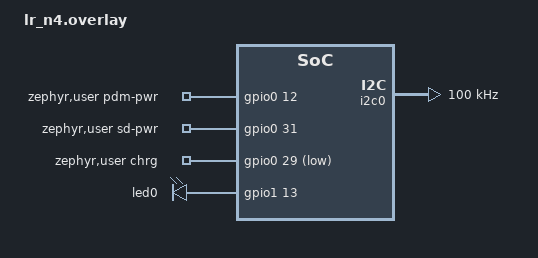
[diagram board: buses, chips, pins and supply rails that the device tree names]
/* LR-N4: our own board around a bare nRF52840 (QIAA, aQFN73), applied after lr_promicro.overlay. The same bootloader
 * and partitions as the ProMicro (nice!nano UF2 bootloader 0.10.0 on S140 6.1.1, the app at 0x26000), and the same
 * pins for the PDM mic (DAT P0.06, CLK P0.08), the SD card (CS P0.20, MOSI P0.22, SCK P0.24, MISO P1.00) and the slide
 * switch (P1.15 to GND = on, CONFIG_LR_SWITCH). What differs is below; the battery is read on AIN0 (P0.02) through a
 * 1M/1M divider (CONFIG_LR_BATTERY_AIN0, battery.c), and the charger's CHRG on P0.29 (chrg-gpios).
 *
 * Power: VDDH comes from the system rail (the battery, or USB through a Schottky diode while plugged in), so the chip
 * runs in high-voltage mode: REG0 (VDDH -> VDD) and REG1 (VDD -> DEC4), each with its DCDC inductor fitted (L1 on
 * DCCH; L3 + L4 on DCC, nRF52840 PS v1.11 7.3.4 configuration 4). The board's Kconfig has BOARD_ENABLE_DCDC and
 * BOARD_ENABLE_DCDC_HV on, and main.c sets DCDCEN and DCDCEN0. VDD is REG0's output, 3.0 V by UICR REGOUT0 = 4 (PS v1.11
 * 5.3.8 and the REGOUT0 register): it is written once with the bootloader over SWD, not by this firmware (the nice!nano
 * 0.10.0 bootloader writes 3.3 V there itself when it finds REGOUT0 erased, boards.c, so the UICR file goes in the same
 * load as the bootloader), and matches
 * the SD card's and the mics' 3.0 V LDOs (SGM2036-3.0), so their I/O levels agree. REG0 needs VDDH 0.3 V above it,
 * which is why the low-battery cut-off stays at 3.3 V (CONFIG_LR_LOW_BATTERY_MV). */
/ {
	zephyr,user {
		/* MIC_PWR: the enable of both mics' LDO (U5, 100k pull-down), not a supply from the pin as on LR-P3 */
		pdm-pwr-gpios = <&gpio0 12 0>;
		/* SD_EN: the card's LDO enable (U3, 100k pull-down) */
		sd-pwr-gpios = <&gpio0 31 GPIO_ACTIVE_HIGH>;
		/* CHRG: the charger's status (TP4054, open drain), read with the pull-up on for 50 us only (battery.c).
		 * LR-N5 / LR-N5-S swap the two balls: lr_n5.overlay, applied after this one, sets both */
		chrg-gpios = <&gpio0 29 GPIO_ACTIVE_LOW>;
	};
};

/* Two mics, MK1 and MK2, on the one CLK / DAT pair: MK1's L/R is tied to its supply and drives DAT on the clock's
 * rising edge, read on the falling edge, MK2's to GND drives the other half (DRA371 datasheet p.7). mic.c records mono
 * on the falling edge (NRF_PDM_MODE_MONO, NRF_PDM_EDGE_LEFTFALLING), LR-P3's setting: MK1 alone. MK2 alone: mono with
 * NRF_PDM_EDGE_LEFTRISING. Both: NRF_PDM_MODE_STEREO with LEFTFALLING, which interleaves MK1 (left) and MK2 (right)
 * samples in each buffer, so MIC_BUFFER_SAMPLES doubles and the codec takes one channel or a mix. */

/* D1's two dies, each through 1k: yellow-green on P0.15 stays led2, the one-LED status flashes (CONFIG_LR_ONE_LED);
 * red on P1.13 is led0: a moment as the mic starts, and main.c's start-up error blinks */
&led0 { gpios = <&gpio1 13 GPIO_ACTIVE_HIGH>; };

/* The IMU (LSM6DS3TR-C, address 0x6A: SA0 to GND) is the XIAO Sense's: powered from P1.08 by the board's
 * lsm6ds3tr-c-en regulator (on at boot), INT1 on P0.11, INT2 open. Its I2C moved to P0.23 (SDA) / P0.19 (SCL), 4.7k
 * pull-ups to the IMU's supply. 100 kHz on the first boards: TWIM at 400 kHz can hold SCL low only ~1.25 us
 * (nRF52840 rev3 errata 219), short of the IMU's 1.3 us tLOW; 390 kHz once the waveform has been measured. The sensor
 * driver reads WHO_AM_I at boot and leaves both accelerometer and gyro at ODR 0 (power-down,
 * CONFIG_LSM6DSL_ACCEL_ODR / GYRO_ODR = 0): nothing here reads it yet. */
&i2c0 { clock-frequency = <I2C_BITRATE_STANDARD>; };
&i2c0_default { group1 { psels = <NRF_PSEL(TWIM_SDA, 0, 23)>, <NRF_PSEL(TWIM_SCL, 0, 19)>; }; };
&i2c0_sleep { group1 { psels = <NRF_PSEL(TWIM_SDA, 0, 23)>, <NRF_PSEL(TWIM_SCL, 0, 19)>; }; };

/* The XIAO overlay's I2S speaker pins: its SCK (P0.29) is the charger's CHRG here, and the driver would drive it low
 * from boot; no speaker on this board */
&i2s0 { status = "disabled"; };
